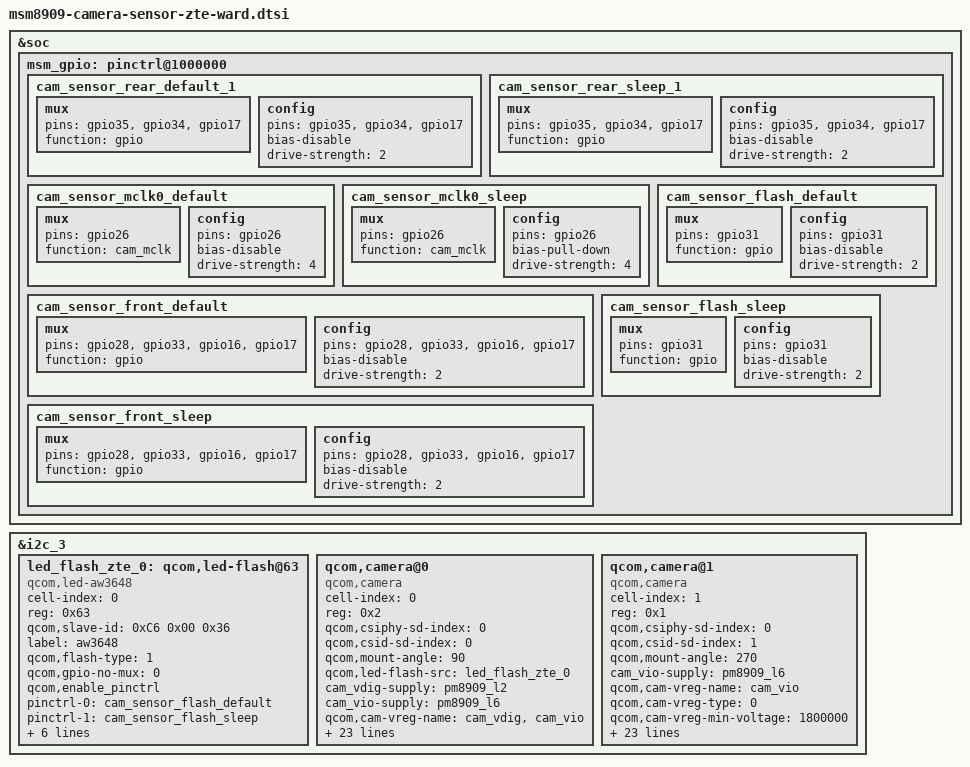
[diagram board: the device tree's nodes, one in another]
/*
 * Copyright (c) 2016, The Linux Foundation. All rights reserved.
 *
 * This program is free software; you can redistribute it and/or modify
 * it under the terms of the GNU General Public License version 2 and
 * only version 2 as published by the Free Software Foundation.
 *
 * This program is distributed in the hope that it will be useful,
 * but WITHOUT ANY WARRANTY; without even the implied warranty of
 * MERCHANTABILITY or FITNESS FOR A PARTICULAR PURPOSE.  See the
 * GNU General Public License for more details.
 */

&soc {
	msm_gpio: pinctrl@1000000{
		cam_sensor_rear_default_1: cam_sensor_rear_default_1 {
				/* RESET, STANDBY VANA*/
				mux {
					pins = "gpio35","gpio34","gpio17";
					function = "gpio";
				};

				config {
					pins = "gpio35","gpio34","gpio17";
					bias-disable; /* No PULL */
					drive-strength = <2>; /* 2 MA */
				};
			};
		cam_sensor_rear_sleep_1: cam_sensor_rear_sleep_1 {
				/* RESET, STANDBY VANA*/
				mux {
					pins = "gpio35","gpio34","gpio17";
					function = "gpio";
				};

				config {
					pins = "gpio35","gpio34","gpio17";
					bias-disable; /* No PULL */
					drive-strength = <2>; /* 2 MA */
				};
			};
		cam_sensor_mclk0_default: cam_sensor_mclk0_default {
			/* MCLK0 */
			mux {
				/* CLK, DATA */
				pins = "gpio26";
				function = "cam_mclk";
			};

			config {
				pins = "gpio26";
				bias-disable; /* No PULL */
				drive-strength = <4>; /* 4 MA */
			};
		};
		cam_sensor_mclk0_sleep: cam_sensor_mclk0_sleep {
			/* MCLK0 */
			mux {
				/* CLK, DATA */
				pins = "gpio26";
				function = "cam_mclk";
			};

			config {
				pins = "gpio26";
				bias-pull-down; /* PULL DOWN */
				drive-strength = <4>; /* 4 MA */
			};
		};
		cam_sensor_front_default: cam_sensor_front_default {
			/* RESET, STANDBY VDIG VANA*/
			mux {
				pins = "gpio28","gpio33","gpio16","gpio17";
				function = "gpio";
			};

			config {
				pins = "gpio28","gpio33","gpio16","gpio17";
				bias-disable; /* No PULL */
				drive-strength = <2>; /* 2 MA */
			};
		};
		cam_sensor_front_sleep: cam_sensor_front_sleep {
			/* RESET, STANDBY VDIG VANA*/
			mux {
				pins = "gpio28","gpio33","gpio16","gpio17";
				function = "gpio";
			};

			config {
				pins = "gpio28","gpio33","gpio16","gpio17";
				bias-disable; /* No PULL */
				drive-strength = <2>; /* 2 MA */
			};
		};
		cam_sensor_flash_default: cam_sensor_flash_default {
		/* FLASH_EN,FLASH_NOW */
			mux {
				pins = "gpio31";
				function = "gpio";
			};
			config {
				pins = "gpio31";
				bias-disable; /* No PULL */
				drive-strength = <2>; /* 2 MA */
			};
		};

		cam_sensor_flash_sleep: cam_sensor_flash_sleep {
			 mux {
				pins = "gpio31";
				function = "gpio";
			};
			config {
				pins = "gpio31";
				bias-disable; /* No PULL */
				drive-strength = <2>; /* 2 MA */
			};
		};
	};
};

&i2c_3 {
	led_flash_zte_0: qcom,led-flash@63 {
		cell-index = <0>;
		reg = <0x63>;
		qcom,slave-id = <0xC6 0x00 0x36>;
		compatible = "qcom,led-aw3648";
		label = "aw3648";
		qcom,flash-type = <1>;
		qcom,gpio-no-mux = <0>;
		qcom,enable_pinctrl;
		pinctrl-names = "cam_flash_default", "cam_flash_suspend";
		pinctrl-0 = <&cam_sensor_flash_default>;
		pinctrl-1 = <&cam_sensor_flash_sleep>;
		gpios = <&msm_gpio 31 0>;
		qcom,gpio-flash-en = <0>;
		qcom,gpio-req-tbl-num = <0>;
		qcom,gpio-req-tbl-flags = <0>;
		qcom,gpio-req-tbl-label = "FLASH_HW_EN";
		qcom,cci-master = <0>;
	};
/*rear camera*/
	qcom,camera@0 {
		cell-index = <0>;
		compatible = "qcom,camera";
		reg = <0x2>;
		qcom,csiphy-sd-index = <0>;
		qcom,csid-sd-index = <0>;
		qcom,mount-angle = <90>;
		qcom,led-flash-src = <&led_flash_zte_0>;
		cam_vdig-supply = <&pm8909_l2>;
		cam_vio-supply = <&pm8909_l6>;
		qcom,cam-vreg-name = "cam_vdig", "cam_vio";
		qcom,cam-vreg-type = <0 0>;
		qcom,cam-vreg-min-voltage = <1200000 1800000>;
		qcom,cam-vreg-max-voltage = <1200000 1800000>;
		qcom,cam-vreg-op-mode = <1200000 1800000>;
		pinctrl-names = "cam_default", "cam_suspend";
		pinctrl-0 = <&cam_sensor_mclk0_default
				&cam_sensor_rear_default_1>;
		pinctrl-1 = <&cam_sensor_mclk0_sleep &cam_sensor_rear_sleep_1>;
		gpios = <&msm_gpio 26 0>,
			<&msm_gpio 35 0>,
			<&msm_gpio 34 0>,
			<&msm_gpio 17 0>;
		qcom,gpio-reset = <1>;
		qcom,gpio-standby = <2>;
		qcom,gpio-vana = <3>;
		qcom,gpio-req-tbl-num = <0 1 2 3>;
		qcom,gpio-req-tbl-flags = <1 0 0 0>;
		qcom,gpio-req-tbl-label = "CAM_MCLK",
			"CAM_RESET",
			"CAM_STANDBY",
			"CAM_VANA";
		qcom,sensor-position = <0>;
		qcom,sensor-mode = <0>;
		qcom,cci-master = <0>;
		status = "ok";
		clocks = <&clock_gcc clk_mclk0_clk_src>,
				<&clock_gcc clk_gcc_camss_mclk0_clk>;
		clock-names = "cam_src_clk", "cam_clk";
		qcom,clock-rates = <24000000 0>;
	};

/*front camera*/
	qcom,camera@1 {
		cell-index = <1>;
		compatible = "qcom,camera";
		reg = <0x1>;
		qcom,csiphy-sd-index = <0>;
		qcom,csid-sd-index = <1>;
		qcom,mount-angle = <270>;
		cam_vio-supply = <&pm8909_l6>;
		qcom,cam-vreg-name = "cam_vio";
		qcom,cam-vreg-type = <0>;
		qcom,cam-vreg-min-voltage = <1800000>;
		qcom,cam-vreg-max-voltage = <1800000>;
		qcom,cam-vreg-op-mode = <1800000>;
		pinctrl-names = "cam_default", "cam_suspend";
		pinctrl-0 = <&cam_sensor_mclk1_default &cam_sensor_front_default>;
		pinctrl-1 = <&cam_sensor_mclk1_sleep &cam_sensor_front_sleep>;
		gpios = <&msm_gpio 27 0>,
			<&msm_gpio 28 0>,
			<&msm_gpio 33 0>,
			<&msm_gpio 16 0>,
			<&msm_gpio 17 0>;
		qcom,gpio-reset = <1>;
		qcom,gpio-standby = <2>;
		qcom,gpio-vdig = <3>;
		qcom,gpio-vana = <4>;
		qcom,gpio-req-tbl-num = <0 1 2 3 4>;
		qcom,gpio-req-tbl-flags = <1 0 0 0 0>;
		qcom,gpio-req-tbl-label = "CAM_MCLK1",
			"CAM_RESET1",
			"CAM_STANDBY1",
			"CAM_VDIG1",
			"CAM_VANA1";
		qcom,sensor-position = <1>;
		qcom,sensor-mode = <0>;
		qcom,cci-master = <0>;
		status = "ok";
		clocks = <&clock_gcc clk_mclk1_clk_src>,
				<&clock_gcc clk_gcc_camss_mclk1_clk>;
		clock-names = "cam_src_clk", "cam_clk";
		qcom,clock-rates = <24000000 0>;
	};
};
